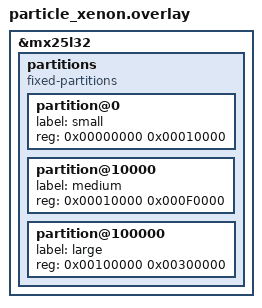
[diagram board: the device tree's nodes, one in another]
/*
 * Copyright (c) 2019 Peter Bigot Consulting, LLC
 *
 * SPDX-License-Identifier: Apache-2.0
 */

/delete-node/ &storage_partition;

&mx25l32 {
	partitions {
		compatible = "fixed-partitions";
		#address-cells = <1>;
		#size-cells = <1>;

		partition@0 {
			label = "small";
			reg = <0x00000000 0x00010000>;
		};
		partition@10000 {
			label = "medium";
			reg = <0x00010000 0x000F0000>;
		};
		partition@100000 {
			label = "large";
			reg = <0x00100000 0x00300000>;
		};
	};
};
